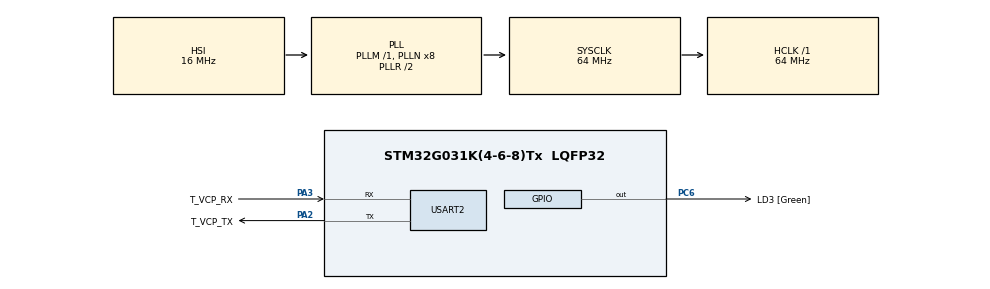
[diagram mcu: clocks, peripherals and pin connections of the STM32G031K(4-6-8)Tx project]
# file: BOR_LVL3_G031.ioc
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Mcu.Family=STM32G0
Mcu.Name=STM32G031K(4-6-8)Tx
Mcu.Package=LQFP32
NVIC.USART2_IRQn=true\:0\:0\:false\:false\:true\:true\:true\:true
PA13.GPIO_Label=T_JTMS
PA13.Mode=Serial_Wire
PA13.Signal=SYS_SWDIO
PA14-BOOT0.GPIO_Label=T_JTCK
PA14-BOOT0.Mode=Serial_Wire
PA14-BOOT0.Signal=SYS_SWCLK
PA2.GPIO_Label=T_VCP_TX
PA2.GPIO_PuPd=GPIO_PULLUP
PA2.Mode=Asynchronous
PA2.Signal=USART2_TX
PA3.GPIO_Label=T_VCP_RX
PA3.GPIO_PuPd=GPIO_PULLUP
PA3.Mode=Asynchronous
PA3.Signal=USART2_RX
PC14-OSC32_IN\ (PC14).Mode=LSE-External-Oscillator
PC14-OSC32_IN\ (PC14).Signal=RCC_OSC32_IN
PC15-OSC32_OUT\ (PC15).Mode=LSE-External-Oscillator
PC15-OSC32_OUT\ (PC15).Signal=RCC_OSC32_OUT
PC6.GPIO_Label=LD3 [Green]
PC6.Signal=GPIO_Output
ProjectManager.HeapSize=0x200
ProjectManager.StackSize=0x400
ProjectManager.TargetToolchain=STM32CubeIDE
RCC.ADCFreq_Value=64000000
RCC.AHBFreq_Value=64000000
RCC.CortexFreq_Value=64000000
RCC.EXTERNAL_CLOCK_VALUE=12288000
RCC.HCLKFreq_Value=64000000
RCC.HSE_VALUE=8000000
RCC.HSI_VALUE=16000000
RCC.SYSCLKFreq_VALUE=64000000
RCC.SYSCLKSource=RCC_SYSCLKSOURCE_PLLCLK
RCC.VCOOutputFreq_Value=128000000
USART2.VirtualMode-Asynchronous=VM_ASYNC
USART2.WordLength=WORDLENGTH_8B
VP_IWDG_VS_IWDG.Mode=IWDG_Activate
board=NUCLEO-G031K8

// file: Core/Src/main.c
/* USER CODE BEGIN Header */
/**
 ******************************************************************************
 * @file           : main.c
 * @brief          : Main program body
 ******************************************************************************
 * @attention
 *
 * Copyright (c) 2025 STMicroelectronics.
 * All rights reserved.
 *
 * This software is licensed under terms that can be found in the LICENSE file
 * in the root directory of this software component.
 * If no LICENSE file comes with this software, it is provided AS-IS.
 *
 ******************************************************************************
 */
/* USER CODE END Header */
#include "main.h"

/* USER CODE BEGIN Includes */
#include "stdio.h"
/* USER CODE END Includes */

/* USER CODE BEGIN PTD */
#define LETTER_c 0x63
#define LETTER_C 0x43
/* USER CODE END PTD */

IWDG_HandleTypeDef hiwdg;

UART_HandleTypeDef huart2;

/* USER CODE BEGIN PV */
uint8_t u8RecBuff[2];
/* USER CODE END PV */

void SystemClock_Config(void);
static void MX_GPIO_Init(void);
static void MX_USART2_UART_Init(void);
static void MX_IWDG_Init(void);

/* USER CODE BEGIN 0 */
void ToggleLED(void)
{
	if(HAL_GPIO_ReadPin(LD3_GPIO_Port, LD3_Pin))
	{
		printf("\033[5;32mLED\033[0m \r\n");
		HAL_GPIO_WritePin(LD3_GPIO_Port, LD3_Pin, GPIO_PIN_RESET);
	}
	else
	{
		printf("\033[1;32mLED\033[0m \r\n");
		HAL_GPIO_WritePin(LD3_GPIO_Port, LD3_Pin, GPIO_PIN_SET);
	}
	HAL_Delay(2000);
}

int __io_putchar(int ch)
{
	HAL_UART_Transmit(&huart2, (uint8_t *)&ch, 1, 100);
	return ch;
}
/* USER CODE END 0 */

int main(void)
{

	/* USER CODE BEGIN 1 */
	FLASH_OBProgramInitTypeDef OptionsBytesStruct;
	/* USER CODE END 1 */

	/* MCU Configuration--------------------------------------------------------*/

	/* Reset of all peripherals, Initializes the Flash interface and the Systick. */
	HAL_Init();

	/* Configure the system clock */
	SystemClock_Config();

	/* Initialize all configured peripherals */
	MX_GPIO_Init();
	MX_USART2_UART_Init();
	/* USER CODE BEGIN 2 */
	if (__HAL_RCC_GET_FLAG(RCC_FLAG_IWDGRST))
	{
		printf("IWDG flag\r\n");
	}
	if (__HAL_RCC_GET_FLAG(RCC_FLAG_OBLRST))
	{
		printf("OBL flag\r\n");
	}
	__HAL_RCC_CLEAR_RESET_FLAGS();
	printf("clear all RCC flags\r\n");

	HAL_FLASHEx_OBGetConfig(&OptionsBytesStruct);
	u8RecBuff[0] = 0;
	u8RecBuff[1] = 0;
	/* USER CODE END 2 */

	/* Infinite loop */
	while (1)
	{

		/* USER CODE BEGIN 3 */
		if(u8RecBuff[1] == 0)
		{
			printf("\033[96mType 'c' or 'C' to change Option Bytes\033[0m \r\n");
			u8RecBuff[1] = 1;
			HAL_UART_Receive_IT(&huart2, u8RecBuff, 1);
		}
		if(u8RecBuff[0] == LETTER_c || u8RecBuff[0] == LETTER_C)
		{
			printf("c or C received, proceeding with OB change\r\n");
			u8RecBuff[0] = 0;
			while(HAL_FLASH_Unlock() != HAL_OK)
			{
				printf("Waiting Flash Unlock\r\n");
			}
			while(HAL_FLASH_OB_Unlock() != HAL_OK)
			{
				printf("Waiting OB Unlock\r\n");
			}
			OptionsBytesStruct.OptionType = OPTIONBYTE_USER ;
			OptionsBytesStruct.USERType = OB_USER_BOR_EN | OB_USER_BOR_LEV;
			OptionsBytesStruct.USERConfig = OB_BOR_ENABLE | OB_BOR_LEVEL_RISING_3 | OB_BOR_LEVEL_FALLING_3;
			while(HAL_FLASHEx_OBProgram(&OptionsBytesStruct) != HAL_OK)
			{
				printf("Waiting OB Program\r\n");
			}
			printf("OB BOR changed\r\n");
			SET_BIT(FLASH->CR, FLASH_CR_OPTSTRT);
			while((FLASH->SR & FLASH_SR_BSY1) != 0)
			{
				;
			}
			printf("OBLauch\r\n");
			MX_IWDG_Init();
			while( HAL_FLASH_OB_Launch()!= HAL_OK)
			{
				printf("OBLauch Failed..retry with IWDG and StandBy Mode\r\n");
				HAL_PWR_EnterSTANDBYMode();
			}
		}
		else
		{
			ToggleLED();
		}
	}
	/* USER CODE END 3 */
}

void SystemClock_Config(void)
{
	RCC_OscInitTypeDef RCC_OscInitStruct = {0};
	RCC_ClkInitTypeDef RCC_ClkInitStruct = {0};

	/** Configure the main internal regulator output voltage
	 */
	HAL_PWREx_ControlVoltageScaling(PWR_REGULATOR_VOLTAGE_SCALE1);

	/** Initializes the RCC Oscillators according to the specified parameters
	 * in the RCC_OscInitTypeDef structure.
	 */
	RCC_OscInitStruct.OscillatorType = RCC_OSCILLATORTYPE_HSI|RCC_OSCILLATORTYPE_LSI;
	RCC_OscInitStruct.HSIState = RCC_HSI_ON;
	RCC_OscInitStruct.HSIDiv = RCC_HSI_DIV1;
	RCC_OscInitStruct.HSICalibrationValue = RCC_HSICALIBRATION_DEFAULT;
	RCC_OscInitStruct.LSIState = RCC_LSI_ON;
	RCC_OscInitStruct.PLL.PLLState = RCC_PLL_ON;
	RCC_OscInitStruct.PLL.PLLSource = RCC_PLLSOURCE_HSI;
	RCC_OscInitStruct.PLL.PLLM = RCC_PLLM_DIV1;
	RCC_OscInitStruct.PLL.PLLN = 8;
	RCC_OscInitStruct.PLL.PLLP = RCC_PLLP_DIV2;
	RCC_OscInitStruct.PLL.PLLQ = RCC_PLLQ_DIV2;
	RCC_OscInitStruct.PLL.PLLR = RCC_PLLR_DIV2;
	if (HAL_RCC_OscConfig(&RCC_OscInitStruct) != HAL_OK)
	{
		Error_Handler();
	}

	/** Initializes the CPU, AHB and APB buses clocks
	 */
	RCC_ClkInitStruct.ClockType = RCC_CLOCKTYPE_HCLK|RCC_CLOCKTYPE_SYSCLK
			|RCC_CLOCKTYPE_PCLK1;
	RCC_ClkInitStruct.SYSCLKSource = RCC_SYSCLKSOURCE_PLLCLK;
	RCC_ClkInitStruct.AHBCLKDivider = RCC_SYSCLK_DIV1;
	RCC_ClkInitStruct.APB1CLKDivider = RCC_HCLK_DIV1;

	if (HAL_RCC_ClockConfig(&RCC_ClkInitStruct, FLASH_LATENCY_2) != HAL_OK)
	{
		Error_Handler();
	}
}

static void MX_IWDG_Init(void)
{

	hiwdg.Instance = IWDG;
	hiwdg.Init.Prescaler = IWDG_PRESCALER_4;
	hiwdg.Init.Window = 4095;
	hiwdg.Init.Reload = 4095;
	if (HAL_IWDG_Init(&hiwdg) != HAL_OK)
	{
		Error_Handler();
	}

}

static void MX_USART2_UART_Init(void)
{

	huart2.Instance = USART2;
	huart2.Init.BaudRate = 115200;
	huart2.Init.WordLength = UART_WORDLENGTH_8B;
	huart2.Init.StopBits = UART_STOPBITS_1;
	huart2.Init.Parity = UART_PARITY_NONE;
	huart2.Init.Mode = UART_MODE_TX_RX;
	huart2.Init.HwFlowCtl = UART_HWCONTROL_NONE;
	huart2.Init.OverSampling = UART_OVERSAMPLING_16;
	huart2.Init.OneBitSampling = UART_ONE_BIT_SAMPLE_DISABLE;
	huart2.Init.ClockPrescaler = UART_PRESCALER_DIV1;
	huart2.AdvancedInit.AdvFeatureInit = UART_ADVFEATURE_NO_INIT;
	if (HAL_UART_Init(&huart2) != HAL_OK)
	{
		Error_Handler();
	}

}

static void MX_GPIO_Init(void)
{
	GPIO_InitTypeDef GPIO_InitStruct = {0};

	/* GPIO Ports Clock Enable */
	__HAL_RCC_GPIOC_CLK_ENABLE();
	__HAL_RCC_GPIOA_CLK_ENABLE();

	/*Configure GPIO pin Output Level */
	HAL_GPIO_WritePin(LD3_GPIO_Port, LD3_Pin, GPIO_PIN_RESET);

	/*Configure GPIO pin : LD3_Pin */
	GPIO_InitStruct.Pin = LD3_Pin;
	GPIO_InitStruct.Mode = GPIO_MODE_OUTPUT_PP;
	GPIO_InitStruct.Pull = GPIO_NOPULL;
	GPIO_InitStruct.Speed = GPIO_SPEED_FREQ_LOW;
	HAL_GPIO_Init(LD3_GPIO_Port, &GPIO_InitStruct);

}

/* USER CODE BEGIN 4 */
void HAL_UART_RxCpltCallback(UART_HandleTypeDef *huart)
{
	if(u8RecBuff[0] != LETTER_c || u8RecBuff[0] != LETTER_C)
	{
		printf("\033[96mType 'c' or 'C' to change Option Bytes\033[0m \r\n");
		HAL_UART_Receive_IT(&huart2, u8RecBuff, 1);
	}
}
/* USER CODE END 4 */

void Error_Handler(void)
{
	__disable_irq();
	while (1)
	{
	}
}
